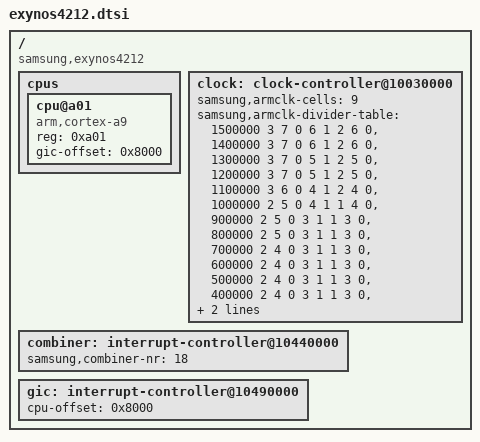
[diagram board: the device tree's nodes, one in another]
/*
 * Samsung's Exynos4212 SoC device tree source
 *
 * Copyright (c) 2012 Samsung Electronics Co., Ltd.
 *		http://www.samsung.com
 *
 * Samsung's Exynos4212 SoC device nodes are listed in this file. Exynos4212
 * based board files can include this file and provide values for board specfic
 * bindings.
 *
 * Note: This file does not include device nodes for all the controllers in
 * Exynos4212 SoC. As device tree coverage for Exynos4212 increases, additional
 * nodes can be added to this file.
 *
 * This program is free software; you can redistribute it and/or modify
 * it under the terms of the GNU General Public License version 2 as
 * published by the Free Software Foundation.
*/

#include "exynos4x12.dtsi"

/ {
	compatible = "samsung,exynos4212", "samsung,exynos4";

	cpus {
		cpu@a01 {
			compatible = "arm,cortex-a9";
			device_type = "cpu";
			reg = <0xa01>;
			gic-offset = <0x8000>;
		};
	};

	clock: clock-controller@10030000 {
		samsung,armclk-cells = <9>;
		samsung,armclk-divider-table = <1500000 3 7 0 6 1 2 6 0>,
					       <1400000 3 7 0 6 1 2 6 0>,
					       <1300000 3 7 0 5 1 2 5 0>,
					       <1200000 3 7 0 5 1 2 5 0>,
					       <1100000 3 6 0 4 1 2 4 0>,
					       <1000000 2 5 0 4 1 1 4 0>,
					       < 900000 2 5 0 3 1 1 3 0>,
					       < 800000 2 5 0 3 1 1 3 0>,
					       < 700000 2 4 0 3 1 1 3 0>,
					       < 600000 2 4 0 3 1 1 3 0>,
					       < 500000 2 4 0 3 1 1 3 0>,
					       < 400000 2 4 0 3 1 1 3 0>,
					       < 300000 2 4 0 2 1 1 3 0>,
					       < 200000 1 3 0 1 1 1 3 0>;
	};

	combiner: interrupt-controller@10440000 {
		samsung,combiner-nr = <18>;
	};

	gic: interrupt-controller@10490000 {
		cpu-offset = <0x8000>;
	};
};
